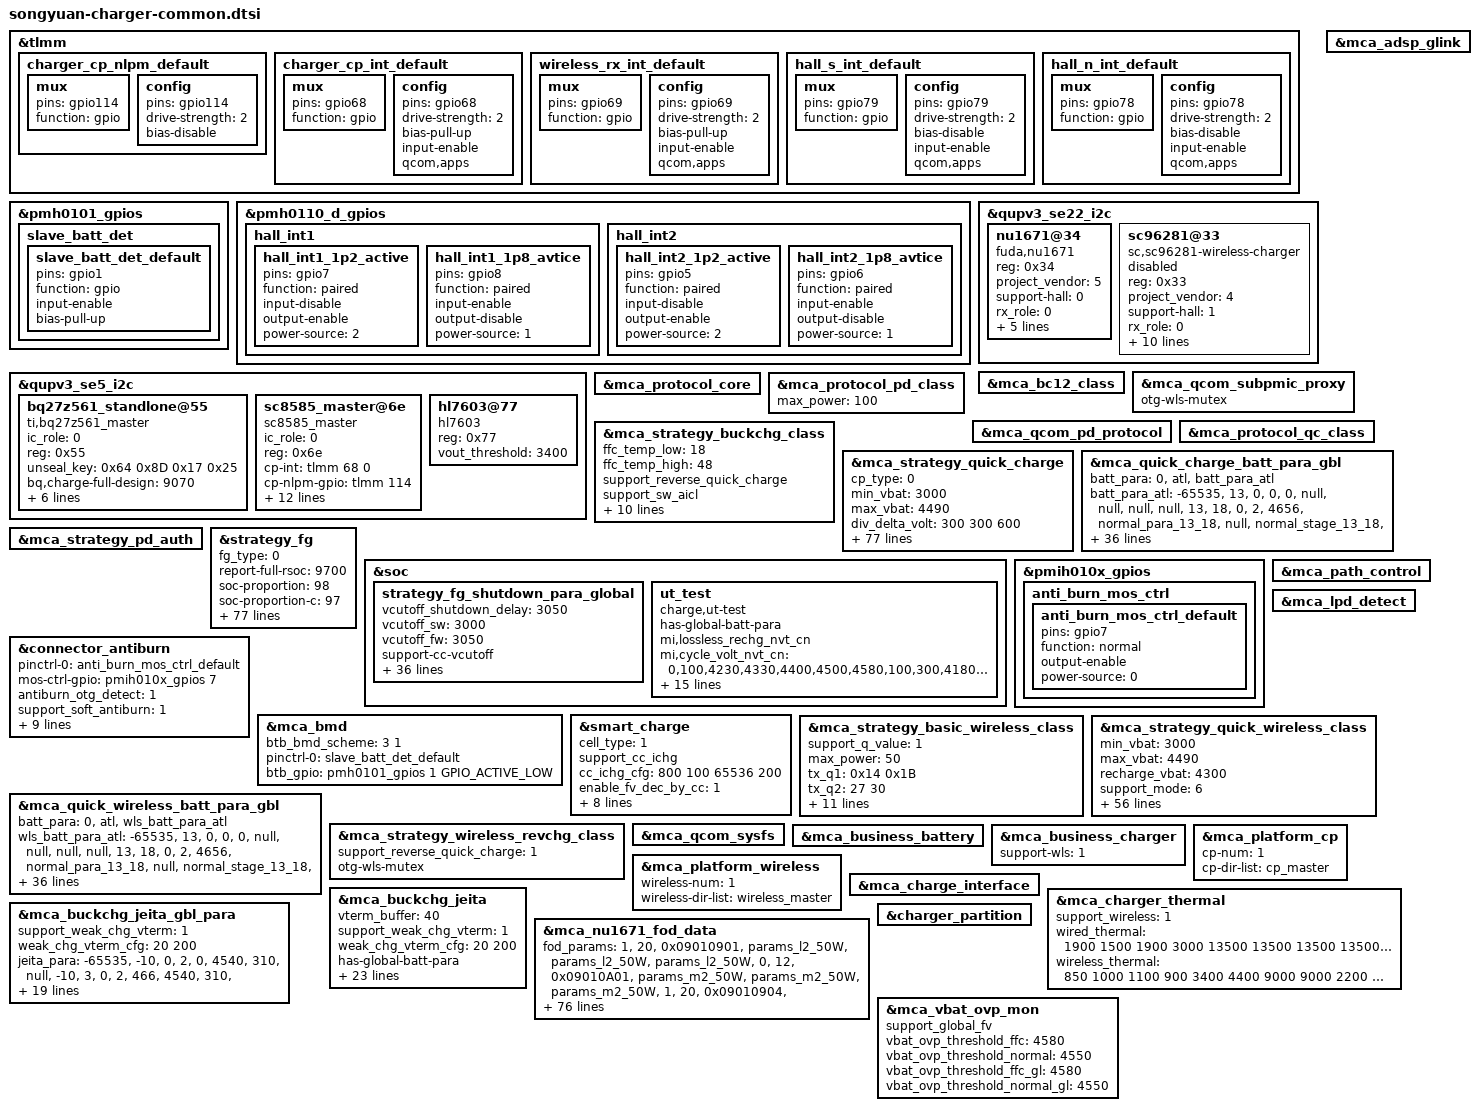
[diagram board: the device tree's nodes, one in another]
#include "mca.dtsi"

&tlmm {
	charger_cp_nlpm_default: charger_cp_nlpm_default {
		mux {
			pins = "gpio114";
			function = "gpio";
		};
		config {
			pins = "gpio114";
			drive-strength = <2>;   /* 2 mA */
			bias-disable;
		};
	};

	charger_cp_int_default: charger_cp_int_default {
		mux {
			pins = "gpio68";
			function = "gpio";
		};
		config {
			pins = "gpio68";
			drive-strength = <2>;   /* 2 mA */
			bias-pull-up;
			input-enable;
			qcom,apps;
		};
	};

	wireless_rx_int_default: wireless_rx_int_default {
		mux {
			pins = "gpio69";
			function = "gpio";
		};

		config {
			pins = "gpio69";
			drive-strength = <2>;
			bias-pull-up;
			input-enable;
			qcom,apps;
		};
	};

	hall_s_int_default: hall_s_int_default {
		mux {
			pins = "gpio79";
			function = "gpio";
		};

		config {
			pins = "gpio79";
			drive-strength = <2>;
			bias-disable;
			input-enable;
			qcom,apps;
		};
	};

	hall_n_int_default: hall_n_int_default {
		mux {
			pins = "gpio78";
			function = "gpio";
		};

		config {
			pins = "gpio78";
			drive-strength = <2>;
			bias-disable;
			input-enable;
			qcom,apps;
		};
	};

};

&pmh0101_gpios {
	slave_batt_det {
		slave_batt_det_default: slave_batt_det_default {
			pins = "gpio1";
			function = "gpio";
			input-enable;
			bias-pull-up;
		};
	};
};

&pmh0110_d_gpios {
	hall_int1 {
		hall_int1_1p2_active: hall_int1_1p2_active {
			pins = "gpio7";
			function = "paired";
			input-disable;
			output-enable;
			power-source = <2>; /* 1.2v */
		};

		hall_int1_1p8_avtice:hall_int1_1p8_avtice {
			pins = "gpio8";
			function = "paired";
			input-enable;
			output-disable;
			power-source = <1>; /* 1.8v */
		};
	};

	hall_int2 {
		hall_int2_1p2_active: hall_int2_1p2_active {
			pins = "gpio5";
			function = "paired";
			input-disable;
			output-enable;
			power-source = <2>; /* 1.2v */
		};

		hall_int2_1p8_avtice:hall_int2_1p8_avtice {
			pins = "gpio6";
			function = "paired";
			input-enable;
			output-disable;
			power-source = <1>; /* 1.8v */
		};
	};
};


&qupv3_se5_i2c {
	status = "ok";
	#address-cells = <1>;
	#size-cells = <0>;
	bq27z561_standlone@55 {
		compatible = "ti,bq27z561_master";
		ic_role = <0>;
		reg = <0x55>;
		unseal_key = /bits/ 8 <0x64 0x8D 0x17 0x25>;
		bq,charge-full-design = <9070>;
		soh_th = <92>;
		cycle_th = <400>;
		cycle_step = <50>;
		resistance-id = <100000>;
		support_batt_manager_4p0;
		support-batt-sn-v2026;
		status = "ok";
	};

	sc8585_master@6e {
		compatible = "sc8585_master";
		status = "ok";
		ic_role = <0>;
		reg = <0x6e>;
		cp-int= <&tlmm 68 0>;
		cp-nlpm-gpio = <&tlmm 114 0x00>;
		pinctrl-names = "default";
		pinctrl-0 = <&charger_cp_nlpm_default>, <&charger_cp_int_default>;
		bat-ovp-threshold = <4700>;
		bat-ovp-alarm-threshold = <4650>;
		bus-ovp-threshold = <21000 12000 6000>;
		usb-ovp-threshold = <21000 14000 7500>;
		bus-ocp-threshold = <5000 5500 5000>;
		wpc-ovp-threshold = <21000>;
		out-ovp-threshold = <5000>;
		pmid2-uvp-threshold = <150 350 100>;
		pmid2-ovp-threshold = <600>;
		ucp-fall-dg = <32000>;
	};

	hl7603@77 {
		compatible = "hl7603";
		reg = <0x77>;
		vout_threshold = <3400>;
	};
};

&qupv3_se22_i2c {
	status = "ok";
	#address-cells = <1>;
	#size-cells = <0>;

	nu1671@34 {
		status = "ok";
		compatible = "fuda,nu1671";
		reg = <0x34>;
		project_vendor = <5>;
		support-hall = <0>;
		rx_role = <0>;
		fw_version_index = <4>;
		pinctrl-names = "default";
		pinctrl-0 = <&wireless_rx_int_default>;
		rx-int = <&tlmm 69 0x00>;
		pwr-det-int = <&tlmm 57 0x00>;
		sleep-rx-gpio = <&tlmm 200 0x00>;

	};

	sc96281@33 {
		status = "disabled";
		compatible = "sc,sc96281-wireless-charger";
		reg = <0x33>;
		project_vendor = <4>;
		support-hall = <1>;
		rx_role = <0>;
		fw_version_index = <1>;
		pinctrl-names = "default";
		pinctrl-0 = <&wireless_rx_int_default>, <&hall_s_int_default>, <&hall_n_int_default>,
					<&hall_int1_1p2_active>, <&hall_int1_1p8_avtice>,
					<&hall_int2_1p2_active>, <&hall_int2_1p8_avtice>;
		rx-int = <&tlmm 69 0x00>;
		pwr-det-int = <&tlmm 57 0x00>;
		sleep-rx-gpio = <&tlmm 200 0x00>;
		hall-s-int = <&tlmm 79 0x00>;
		hall-n-int = <&tlmm 78 0x00>;
	};
};

&mca_adsp_glink {
	status = "ok";
};

&mca_bc12_class {
	status = "ok";
};

&mca_qcom_subpmic_proxy {
	status = "ok";
	otg-wls-mutex;
};

&mca_protocol_core {
	status = "ok";
};

&mca_protocol_pd_class {
	status = "ok";
	max_power = <100>;
};

&mca_qcom_pd_protocol {
	status = "ok";
};

&mca_protocol_qc_class {
	status = "ok";
};


&mca_strategy_buckchg_class {
	status = "ok";
	ffc_temp_low = <18>;
	ffc_temp_high = <48>;
	support_reverse_quick_charge;
	support_sw_aicl;
	support_revchg_screenon;
	support_pps_100w = <3>;
	support_revchg_27w;
	revchg_soc_thr = <60>;
	/* BS(Battery Sense) Vacc enable. Params inherited from mca.dtsi. */
	support_pmic_vacc;
	pmic_iterm_compensation = <70>;
	support_pmic_iterm_dynamics_adjust;
	/* <minimum ITERM, compensation (mA)> */
	pmic_iterm_dynamics_adjust_config =
		<0 30>, /* 0-173mA: compensation 30mA */
		<174 70>;
	ffc_terminated_by_cp = <1>;
};

&mca_strategy_quick_charge {
	status = "ok";
	cp_type = <0>;
	min_vbat = <3000>;
	max_vbat = <4490>;
	div_delta_volt = <300 300 600>;
	div_single_curr = <4500 11000 18400>;
	div_max_curr = <5000 12000 18400>;
	non_mi_pps_max_curr = <4500 11000 18400>;
	support_mode = <6>;
	has-global-batt-para;
	support_cp_vfc = <1>;
	real_curr_max = <17500>;
	support_monitor_current = <17600>;
	curr_monitor_time_s = <120>;
	support_cancel_compensation;
	max_vbat_threshold = <4580>;
	en_buck_parallel_chg = <1>;
	buck_icl_fcc_curr = <1000 3000>;
	buck_en_th = <13000 2500>;
	buck_dis_th = <13000 3850>;
	cp_switch_pmic_th = <1000>;
	drop_fv_value = <10>; /* BS strategy -10mv, drop fv value for BS */

	/* BS(Battery Sense) PMIC&CP dynamic parallel charging (wired) enable.
	 * Params inherited from mca.dtsi.
	 */
	drop_fv_cycle_pdc = <65535>;
	support_pmic_dynamic_chg;

	use-terminate-staged;
	curr_terminate_hys = <300>;
	terminate_staged_para =
		<110 1000>,
		<105 3000>;
	vfc_iout_fsw_map =
		"6000", "720",
		"0", "420";
	batt_depolarize_time_s = <60>;

	/* volt_ratio, cur_gap, vbat_gap, vstep_ratio */
	vstep_para =
		"1", "300", "2000", "0", "2",
		"2", "300", "2000", "0", "4",
		"4", "300", "8000", "0", "25",
		"4", "300", "4000", "20", "17",
		"4", "300", "2000", "10", "5",
		"4", "300", "1200", "10", "5",
		"4", "300", "800", "0", "2",
		"1", "800", "2000", "0", "2",
		"2", "800", "2000", "0", "4",
		"4", "800", "8000", "0", "10",
		"4", "800", "6000", "0", "5",
		"4", "800", "4000", "0", "2";

	batt_para =
		"0", "atl", "batt_para_atl";
	/* temp_low, temp_high, low_hys, high_hys, max_curr, normal_para, ffc_para, normal_stage, ffc_stage */
	batt_para_atl =
		"-65535", "13", "0", "0", "0", "null", "null", "null", "null",
		"13", "18", "0", "2", "5178", "normal_para_atl_13_18", "null", "normal_stage_atl_13_18", "null",
		"18", "23", "0", "1", "12945", "normal_para_atl_18_23", "ffc_para_atl_18_23", "ffc_stage_atl_18_23", "ffc_stage_atl_18_23",
		"23", "35", "0", "0", "18300", "normal_para_atl_23_35", "ffc_para_atl_23_35", "ffc_stage_atl_23_35", "ffc_stage_atl_23_35",
		"35", "40", "1", "0", "18300", "normal_para_atl_35_40", "ffc_para_atl_35_40", "ffc_stage_atl_35_40", "ffc_stage_atl_35_40",
		"40", "48", "1", "0", "18300", "normal_para_atl_40_48", "ffc_para_atl_40_48", "ffc_stage_atl_40_48", "ffc_stage_atl_40_48",
		"48", "65535", "2", "0", "0", "null", "null", "null", "null";

	/* volt, curr_max, curr_min */
	normal_para_atl_13_18 =
		"3900", "5178", "3452",
		"4545", "3452", "432";
	normal_stage_atl_13_18 = <0 1 0 0>;

	normal_para_atl_18_23 =
		"3900", "12945", "9493",
		"4000", "9493", "6904",
		"4150", "6904", "3452",
		"4525", "3452", "432";
	ffc_para_atl_18_23 =
		"3900", "12945", "9493",
		"4000", "9493", "6904",
		"4150", "6904", "3452",
		"4570", "3452", "1014";
	ffc_stage_atl_18_23 = <0 1 0 0 0 0 0 0>;

	normal_para_atl_23_35 =
		"4230", "18300", "12400",
		"4330", "12400", "10356",
		"4400", "10356", "8630",
		"4500", "8630", "6904",
		"4525", "6904", "432";
	ffc_para_atl_23_35 =
		"4230", "18300", "12400",
		"4330", "12400", "10356",
		"4400", "10356", "8630",
		"4500", "8630", "6904",
		"4570", "6904", "1445";
	ffc_stage_atl_23_35 = <0 1 0 0 0 0 0 0 0 0>;

	normal_para_atl_35_40 =
		"4230", "18300", "12400",
		"4330", "12400", "10356",
		"4400", "10356", "8630",
		"4500", "8630", "6904",
		"4505", "6904", "432";
	ffc_para_atl_35_40 =
		"4230", "18300", "12400",
		"4330", "12400", "10356",
		"4400", "10356", "8630",
		"4500", "8630", "6904",
		"4570", "6904", "2107";
	ffc_stage_atl_35_40 = <0 1 0 0 0 0 0 0 0 0>;

	normal_para_atl_40_48 =
		"4230", "18300", "12400",
		"4330", "12400", "10356",
		"4400", "10356", "8630",
		"4495", "8630", "6904",
		"4495", "6904", "432";
	ffc_para_atl_40_48 =
		"4230", "18300", "12400",
		"4330", "12400", "10356",
		"4400", "10356", "8630",
		"4500", "8630", "6904",
		"4570", "6904", "2958";
	ffc_stage_atl_40_48 = <0 1 0 0 0 0 0 0 0 0>;
};

&mca_quick_charge_batt_para_gbl {
	batt_para =
		"0", "atl", "batt_para_atl";
	/* temp_low, temp_high, low_hys, high_hys, max_curr, normal_para, ffc_para, normal_stage, ffc_stage */
	batt_para_atl =
		"-65535", "13", "0", "0", "0", "null", "null", "null", "null",
		"13", "18", "0", "2", "4656", "normal_para_13_18", "null", "normal_stage_13_18", "null",
		"18", "23", "0", "1", "11640", "normal_para_18_23", "null", "normal_stage_13_18", "null",
		"23", "35", "0", "0", "18300", "normal_para_23_35", "ffc_para_23_35", "ffc_stage_23_35", "ffc_stage_23_35",
		"35", "40", "1", "0", "18300", "normal_para_35_40", "ffc_para_35_40", "ffc_stage_35_40", "ffc_stage_35_40",
		"40", "48", "1", "0", "18300", "normal_para_40_48", "ffc_para_40_48", "ffc_stage_40_48", "ffc_stage_40_48",
		"48", "65535", "2", "0", "0", "null", "null", "null", "null";

	/* volt, curr_max, curr_min */
	normal_para_13_18 =
		"4200", "4656", "3104",
		"4545", "3104", "621";
	normal_stage_13_18 = <0 1 0 0>;

	normal_para_18_23 =
		"4250", "11640", "9312",
		"4525", "9312", "621";

	normal_para_23_35 =
		"4110", "18300", "12400",
		"4210", "12400", "11640",
		"4400", "11640", "9312",
		"4500", "9312", "7760",
		"4525", "7760", "621";
	ffc_para_23_35 =
		"4110", "18300", "12400",
		"4210", "12400", "11640",
		"4400", "11640", "9312",
		"4500", "9312", "7760",
		"4575", "7760", "1990";
	ffc_stage_23_35 = <0 1 0 0 0 0 0 0 0 0>;

	normal_para_35_40 =
		"4110", "18300", "12400",
		"4210", "12400", "11640",
		"4400", "11640", "9312",
		"4500", "9312", "7760",
		"4505", "7760", "621";
	ffc_para_35_40 =
		"4110", "18300", "12400",
		"4210", "12400", "11640",
		"4400", "11640", "9312",
		"4500", "9312", "7760",
		"4575", "7760", "3298";
	ffc_stage_35_40 = <0 1 0 0 0 0 0 0 0 0>;

	normal_para_40_48 =
		"4110", "18300", "12400",
		"4210", "12400", "11640",
		"4400", "11640", "9312",
		"4495", "9312", "7760",
		"4495", "7760", "621";
	ffc_para_40_48 =
		"4110", "18300", "12400",
		"4210", "12400", "11640",
		"4400", "11640", "9312",
		"4500", "9312", "7760",
		"4575", "7760", "4982";
	ffc_stage_40_48 = <0 1 0 0 0 0 0 0 0 0>;
};

&mca_strategy_pd_auth {
	status = "ok";
};

&strategy_fg {
	status = "ok";
	fg_type = <0>;
	report-full-rsoc = <9700>;
	soc-proportion = <98>;
	soc-proportion-c = <97>;
	support-pnc;
	support-vpack-low-shutdown;
	has_global_shutdown_para;
	vcutoff_shutdown_delay = <2850>;
	vcutoff_sw = <2800>;
	vcutoff_fw = <2850>;
	vterm_delta = <7>;
	support-normal-early-done-rechg = <1>;
	/* rsoc_min_thr, rsoc_max_thr, rest_time */
	normal-early-done-rechg-cfg = <97 100 300>;
	clear_CC_per_hundred = <0>;

	/* BS(Battery Sense) Vacc + CP dynamic enable. Params inherited from mca.dtsi. */
	support_pmic_vacc;
	support_pmic_cp_dynamic;

	support-cc-vcutoff;
	/* temp_low, temp_high, low_temp_hys, high_temp_hys, vterm_para_name */
	cc_vcutoff_cfg =
		"-65535", "-6", "0", "2", "cc_para0",
		"-6", "0", "2", "2", "cc_para1",
		"0", "10", "2", "2", "cc_para2",
		"10", "60", "2", "0", "cc_para3",
		"60", "65535", "2", "0", "cc_para4";
	/* cycle_count, vterm_fw, vterm_shutdown_delay, vempty */
	cc_para0 =
		"400", "2650", "2600", "2500",
		"800", "2700", "2650", "2600",
		"1200", "2800", "2750", "2700",
		"65535", "2850", "2800", "2750";
	cc_para1 =
		"400", "2650", "2600", "2500",
		"800", "2700", "2650", "2600",
		"1200", "2800", "2750", "2700",
		"65535", "2950", "2900", "2850";
	cc_para2 =
		"400", "2650", "2650", "2600",
		"800", "2850", "2850", "2800",
		"1200", "2950", "2950", "2900",
		"65535", "3050", "3050", "3000";
	cc_para3 =
		"400", "2850", "2850", "2800",
		"800", "3020", "3020", "2970",
		"1200", "3120", "3120", "3070",
		"65535", "3200", "3200", "3150";
	cc_para4 =
		"65535", "3200", "3200", "3150";

	support-dod-vcutoff-v2;
	weight = <20 18 15>;
	/* temp_low, temp_high, low_temp_hys, high_temp_hys, vterm_para_name */
	dod_vcutoff_cfg =
		"-65535", "-6", "0", "2", "dod_para0",
		"-6", "0", "2", "2", "dod_para1",
		"0", "10", "2", "2", "dod_para2",
		"10", "60", "2", "0", "dod_para3",
		"60", "65535", "2", "0", "dod_para4";
	/* dod_count, vterm_fw, vterm_shutdown_delay, vempty */
	dod_para0 =
		"90", "2650", "2600", "2500",
		"169", "2700", "2650", "2600",
		"452", "2800", "2750", "2700",
		"1051", "2850", "2800", "2750",
		"65535", "2950", "2900", "2850";
	dod_para1 =
		"90", "2650", "2600", "2500",
		"169", "2700", "2650", "2600",
		"452", "2800", "2750", "2700",
		"1051", "2950", "2900", "2850",
		"65535", "3050", "3000", "2950";
	dod_para2 =
		"90", "2650", "2650", "2600",
		"169", "2850", "2850", "2800",
		"452", "2950", "2950", "2900",
		"1051", "3050", "3050", "3000",
		"65535", "3110", "3110", "3060";
	dod_para3 =
		"90", "2850", "2850", "2800",
		"169", "3020", "3020", "2970",
		"452", "3120", "3120", "3070",
		"1051", "3200", "3200", "3150",
		"65535", "3250", "3250", "3200";
	dod_para4 =
		"65535", "3250", "3250", "3200";

	adapt_power = <100>;
	model-name = "SONGYUAN_9070mah_100w";
	model-name-global = "SONGYUAN_8050mah_100w";
	support_full_design_gl;
	charge-full-design = <9070>;
	capacity_comp = <0>;
	capacity_comp_gl = <0>;
	support_dynamic_capacity_comp;
	support_dtpt = <1>;
	charge-full-design-gl = <8050>;
	fg_hightemp_vterm = <4200>;
	support-lossless-rechg = <1>;
	lossless-rechg-nor = <0>;
	lossless_rechg_cfg = <18 47 300>;
	support_normal_force_full;
	normal_force_full_hys = <116>;
	support_clear_cycle;
	suppot_RSOC_0_smooth = <1>;
	smooth_temp_unit = <0 150>; //15℃
	smooth_curr_unit = <0 300000 600000 1000000 >;
	smooth_vol_offset = <0x80000000 0 100 200 300 >;
	dischg_smooth_low_temp_unit = <
		10 10 10 10
		20 10 10 10
		40 20 10 10
		80 40 30 20
		150 80 70 50 >;
	dischg_smooth_high_temp_unit = <
		10 10 10 10
		30 20 10 10
		60 40 20 10
		150 70 50 40
		200 150 100 70 >;
	support_extreme_cold = <2>;
	extreme_cold_temp_compemsation =
		"2147483647", "50", "90",
		"2147483647", "600", "80";
};

&soc {
	strategy_fg_shutdown_para_global {
		vcutoff_shutdown_delay = <3050>;
		vcutoff_sw = <3000>;
		vcutoff_fw = <3050>;
		support-cc-vcutoff;
		/* temp_low, temp_high, low_temp_hys, high_temp_hys, vterm_para_name */
		cc_vcutoff_cfg =
			"-65535", "-6", "0", "2", "cc_para0",
			"-6", "0", "2", "2", "cc_para1",
			"0", "10", "2", "2", "cc_para2",
			"10", "60", "2", "0", "cc_para3",
			"60", "65535", "2", "0", "cc_para4";
		/* cycle_count, vterm_fw, vterm_shutdown_delay, vempty */
		cc_para0 =
			"400", "2650", "2600", "2500",
			"800", "2700", "2650", "2600",
			"1200", "2800", "2750", "2700",
			"65535", "2850", "2800","2750";
		cc_para1 =
			"400", "2650", "2600", "2500",
			"800", "2700", "2650", "2600",
			"1200", "2800", "2750", "2700",
			"65535", "2950", "2900","2850";
		cc_para2 =
			"400", "2650", "2650", "2600",
			"800", "2850", "2850", "2800",
			"1200", "2950", "2950", "2900",
			"65535", "3050", "3050","3000";
		cc_para3 =
			"400", "2850", "2850", "2800",
			"800", "3020", "3020", "2970",
			"1200", "3120", "3120", "3070",
			"65535", "3200", "3200","3150";
		cc_para4 =
			"65535", "3200", "3200","3150";
		support-dod-vcutoff-v2;
		weight = <20 18 15>;
		/* temp_low, temp_high, low_temp_hys, high_temp_hys, vterm_para_name */
		dod_vcutoff_cfg =
			"-65535", "-6", "0", "2", "dod_para0",
			"-6", "0", "2", "2", "dod_para1",
			"0", "10", "2", "2", "dod_para2",
			"10", "60", "2", "0", "dod_para3",
			"60", "65535", "2", "0", "dod_para4";
		/* dod_count, vterm_fw, vterm_shutdown_delay, vempty */
		dod_para0 =
			"90", "2650", "2600", "2500",
			"169", "2700", "2650", "2600",
			"452", "2800", "2750", "2700",
			"1051", "2850", "2800", "2750",
			"65535", "2950", "2900", "2850";
		dod_para1 =
			"90", "2650", "2600", "2500",
			"169", "2700", "2650", "2600",
			"452", "2800", "2750", "2700",
			"1051", "2950", "2900", "2850",
			"65535", "3050", "3000", "2950";
		dod_para2 =
			"90", "2650", "2650", "2600",
			"169", "2850", "2850", "2800",
			"452", "2950", "2950", "2900",
			"1051", "3050", "3050", "3000",
			"65535", "3110", "3110", "3060";
		dod_para3 =
			"90", "2850", "2850", "2800",
			"169", "3020", "3020", "2970",
			"452", "3120", "3120", "3070",
			"1051", "3200", "3200", "3150",
			"65535", "3250", "3250", "3200";
		dod_para4 =
			"65535", "3250", "3250", "3200";
	};
};

&pmih010x_gpios {
	anti_burn_mos_ctrl {
		anti_burn_mos_ctrl_default: anti_burn_mos_ctrl_default {
			pins = "gpio7";
			function = "normal";
			output-enable;
			//drive-strength = <2>;
			power-source = <0>;
		};
	};
};

&connector_antiburn {
	status = "ok";
	pinctrl-names = "default";
	pinctrl-0 = <&anti_burn_mos_ctrl_default>;
	mos-ctrl-gpio = <&pmih010x_gpios 7 0>;
	antiburn_otg_detect = <1>;
	support_soft_antiburn = <1>;
	support_hw_antiburn = <1>;
	use_double_ntc = <1>;
	monitor_interval = <1000>;
	thermal-zone-name = "conn_therm";
	thermal-zone-name2 = "conn_therm2";
	max_temp_increase_rate = <4>; /*ntc temperature increase speed per second.*/
	otg_boost_src = <2>; /* BOOST_SRC_EXTERNAL */
	en_src = <0>; /* OTG_EN_BOOST */
	thermal-board-temp-name = "board_sensor_therm";
};

&mca_bmd {
	status = "ok";
	btb_bmd_scheme = <3 1>;
	pinctrl-names = "default";
	pinctrl-0 = <&slave_batt_det_default>;
	btb_gpio = <&pmh0101_gpios 1 GPIO_ACTIVE_LOW>;
};

&smart_charge {
	status = "ok";
	cell_type = <1>;
	support_cc_ichg;
	/* cyclecount delta_ichg*/
	cc_ichg_cfg = <
		800 100
		65536 200>;
	enable_fv_dec_by_cc = <1>;
	smart_bypass_support = <1>;
	smart_bypass_entry_soc = <40>;
	smart_bypass_high_lmt_cfg = <
		(-100) 150 5 5 4500
		151 200 5 5 4500
		201	250	5 5 4500
		251	300	5 5 3500
		301	370	5 5 2500
		371	800	5 5 1000>;
	smart_bypass_med_lmt_cfg = <
		(-100) 150 5 5 18400
		151	200	5 5 18400
		201	250	5 5 18400
		251	300	5 5 8000
		301	370	5 5 5000
		371	800	5 5 2000>;
	smart_bypass_low_lmt_cfg = <
		(-100) 150 5 5 18400
		151	200	5 5 18400
		201	250	5 5 18400
		251	300	5 5 9000
		301	370	5 5 5000
		371	800	5 5 3000>;
};

&mca_path_control {
	status = "ok";
};

&mca_lpd_detect {
	status = "ok";
};

&mca_strategy_basic_wireless_class {
	status = "ok";
	support_q_value = <1>;
	max_power = <50>;
	/* low_inductance_tx_50w, low_inductance_tx_80w */
	tx_q1 = /bits/ 8 <0x14 0x1B>;
	tx_q2 = <27 30>;
	rx_max_iout = <2650 2650>;
	wls_vdd_src = <2>;
	ffc_temp_low = <15>;
	ffc_temp_high = <48>;
	support-hall = <0>;

	support-dynamic-cp = <1>;
	dynamic-cp-uuid = <0x09010A01>;
	dynamic-cp-min-tx-adapter = <14>;
	dynamic-cp-4to2-threshold = <6000>;
	dynamic-cp-2-1-max-fcc = <9200>;

	/* BS(Battery Sense) Vacc for wireless. Params inherited from mca.dtsi. */
	support_pmic_vacc;
};

&mca_strategy_quick_wireless_class {
	status = "ok";
	min_vbat = <3000>;
	max_vbat = <4490>;
	recharge_vbat = <4300>;
	support_mode = <6>;
	div_single_curr = <0 9200 9200>;
	div_max_curr = <0 9200 9200>;
	has-global-batt-para;
	support-hall = <0>;
	exit_fcc = <1000 1500 1500>;

	/* BS(Battery Sense) PMIC&CP dynamic parallel charging (wireless) enable.
	 * Params inherited from mca.dtsi.
	 */
	support_pmic_dynamic_chg;

	batt_para =
		"0", "atl", "wls_batt_para_atl";
	/* temp_low, temp_high, low_temp_hys, high_temp_hys, max_current, volt_para_name stage_para_name*/
	wls_batt_para_atl =
		"-65535", "13", "0", "0", "0", "null", "null", "null", "null",
		"13", "18", "0", "2", "5178", "normal_para_atl_13_18", "null", "normal_stage_atl_13_18", "null",
		"18", "23", "0", "1", "12945", "normal_para_atl_18_23", "ffc_para_atl_18_23", "ffc_stage_atl_18_23", "ffc_stage_atl_18_23",
		"23", "35", "0", "0", "17600", "normal_para_atl_23_35", "ffc_para_atl_23_35", "ffc_stage_atl_23_35", "ffc_stage_atl_23_35",
		"35", "40", "1", "0", "17600", "normal_para_atl_35_40", "ffc_para_atl_35_40", "ffc_stage_atl_35_40", "ffc_stage_atl_35_40",
		"40", "48", "1", "0", "17600", "normal_para_atl_40_48", "ffc_para_atl_40_48", "ffc_stage_atl_40_48", "ffc_stage_atl_40_48",
		"48", "65535", "2", "0", "0", "null", "null", "null", "null";

	/* volt, curr_max, curr_min */
	normal_para_atl_13_18 =
		"3900", "5178", "3452",
		"4550", "3452", "432";
	normal_stage_atl_13_18 = <0 1 0 0>;

	normal_para_atl_18_23 =
		"3900", "12945", "9493",
		"4000", "9493", "6904",
		"4150", "6904", "3452",
		"4530", "3452", "432";
	ffc_para_atl_18_23 =
		"3900", "12945", "9493",
		"4000", "9493", "6904",
		"4150", "6904", "3452",
		"4520", "3452", "1014";
	ffc_stage_atl_18_23 = <0 1 0 1 0 1 0 1 0 1>;

	normal_para_atl_23_35 =
		"4230", "17600", "12400",
		"4330", "12400", "10356",
		"4400", "10356", "8630",
		"4500", "8630", "6904",
		"4530", "6904", "432";
	ffc_para_atl_23_35 =
		"4230", "17600", "12400",
		"4330", "12400", "10356",
		"4400", "10356", "8630",
		"4500", "8630", "6904",
		"4520", "6904", "1445";
	ffc_stage_atl_23_35 = <0 1 0 1 0 1 0 1 0 1>;

	normal_para_atl_35_40 =
		"4230", "17600", "12400",
		"4330", "12400", "10356",
		"4400", "10356", "8630",
		"4500", "8630", "6904",
		"4510", "6904", "432";
	ffc_para_atl_35_40 =
		"4230", "17600", "12400",
		"4330", "12400", "10356",
		"4400", "10356", "6904",
		"4500", "6904", "2107";
	ffc_stage_atl_35_40 = <0 1 0 1 0 1 0 1 0 1>;

	normal_para_atl_40_48 =
		"4230", "17600", "12400",
		"4330", "12400", "10356",
		"4400", "10356", "8630",
		"4500", "8630", "6904",
		"4500", "6904", "432";
	ffc_para_atl_40_48 =
		"4230", "17600", "12400",
		"4330", "12400", "10356",
		"4400", "10356", "6904",
		"4500", "6904", "2958";
	ffc_stage_atl_40_48 = <0 1 0 1 0 1 0 1 0 1>;

	vstep_para =
		"1", "2000", "2",
		"2", "4000", "25",
		"2", "3000", "25",
		"2", "2000", "4",
		"4", "4000", "25",
		"4", "3000", "25",
		"4", "2000", "6",
		"4", "1000", "3",
		"4", "500", "2",
		"4", "200", "1";
};

&mca_quick_wireless_batt_para_gbl {
	batt_para =
		"0", "atl", "wls_batt_para_atl";
	/* temp_low, temp_high, low_temp_hys, high_temp_hys, max_current, volt_para_name stage_para_name*/
	wls_batt_para_atl =
		"-65535", "13", "0", "0", "0", "null", "null", "null", "null",
		"13", "18", "0", "2", "4656", "normal_para_13_18", "null", "normal_stage_13_18", "null",
		"18", "23", "0", "1", "11640", "normal_para_18_23", "null", "normal_stage_13_18", "null",
		"23", "35", "0", "0", "17600", "normal_para_23_35", "ffc_para_23_35", "ffc_stage_23_35", "ffc_stage_23_35",
		"35", "40", "1", "0", "17600", "normal_para_35_40", "ffc_para_35_40", "ffc_stage_35_40", "ffc_stage_35_40",
		"40", "48", "1", "0", "17600", "normal_para_40_48", "ffc_para_40_48", "ffc_stage_40_48", "ffc_stage_40_48",
		"48", "65535", "0", "0", "0", "null", "null", "null", "null";

	/* volt, curr_max, curr_min */
	normal_para_13_18 =
		"4200", "4656", "3104",
		"4550", "3104", "621";
	normal_stage_13_18 = <0 1 0 0>;

	normal_para_18_23 =
		"4250", "11640", "9312",
		"4530", "9312", "621";

	normal_para_23_35 =
		"4110", "17600", "12400",
		"4210", "12400", "11640",
		"4400", "11640", "9312",
		"4500", "9312", "7760",
		"4530", "7760", "621";
	ffc_para_23_35 =
		"4110", "17600", "12400",
		"4210", "12400", "11640",
		"4400", "11640", "9312",
		"4500", "9312", "7760",
		"4580", "7760", "1990";
	ffc_stage_23_35 = <0 1 0 0 0 0 0 0 0 0>;

	normal_para_35_40 =
		"4110", "17600", "12400",
		"4210", "12400", "11640",
		"4400", "11640", "9312",
		"4500", "9312", "7760",
		"4510", "7760", "621";
	ffc_para_35_40 =
		"4110", "17600", "12400",
		"4210", "12400", "11640",
		"4400", "11640", "9312",
		"4500", "9312", "7760",
		"4580", "7760", "3298";
	ffc_stage_35_40 = <0 1 0 0 0 0 0 0 0 0>;

	normal_para_40_48 =
		"4110", "17600", "12400",
		"4210", "12400", "11640",
		"4400", "11640", "9312",
		"4500", "9312", "7760",
		"4500", "7760", "621";
	ffc_para_40_48 =
		"4110", "17600", "12400",
		"4210", "12400", "11640",
		"4400", "11640", "9312",
		"4500", "9312", "7760",
		"4580", "7760", "4982";
	ffc_stage_40_48 = <0 1 0 0 0 0 0 0 0 0>;
};

&mca_strategy_wireless_revchg_class {
	status = "ok";
	support_reverse_quick_charge = <1>;
	otg-wls-mutex;
};

&mca_qcom_sysfs {
	status = "ok";
};

&mca_business_battery {
	status = "ok";
};

&mca_business_charger {
	support-wls = <1>;
	status = "ok";
};

&mca_platform_cp {
	status = "ok";
	cp-num = <1>;
	cp-dir-list = "cp_master";
};

&mca_platform_wireless {
	status = "ok";
	wireless-num = <1>;
	wireless-dir-list = "wireless_master";
};

&mca_charge_interface {
	status = "ok";
};

&mca_charger_thermal {
	status = "ok";
	support_wireless = <1>;
	/* 5v_in 9v_in 5v_ichg 9v_ichg div1_single div1_multi div2_single div2_multi div4_single div4_multi*/
	wired_thermal = <
		1900 1500 1900 3000 13500 13500 13500 13500 13500 13500 /* level 1 */
		1900 1500 1900 3000 11000 11000 11000 11000 11000 11000 /* level 2 */
		1900 1500 1900 3000 9000  9000  9000  9000  9000  9000  /* level 3 */
		1900 1450 1900 3000 8000  8000  8000  8000  8000  8000  /* level 4 */
		1900 1400 1900 3000 7000  7000  7000  7000  7000  7000  /* level 5 */
		1900 1350 1900 2800 6000  6000  6000  6000  6000  6000  /* level 6 */
		1900 1300 1900 2600 5000  5000  5000  5000  5000  5000  /* level 7 */
		1900 1150 1900 2310 4000  4000  4000  4000  4000  4000  /* level 8 */
		1700 1100 1700 2200 3500  3500  3500  3500  3500  3500  /* level 9 */
		1600 1000 1600 2000 3000  3000  3000  3000  3000  3000  /* level 10 */
		1400 900  1500 2000 2500  2500  2500  2500  2500  2500  /* level 11 */
		1200 850  1500 2000 2000  2000  2000  2000  2000  2000  /* level 12 */
		1100 750  1500 1500 1500  1500  1500  1500  1500  1500  /* level 13 */
		1100 650  1000 1000 1000  1000  1000  1000  1000  1000  /* level 14 */
		1100 600  500  500  500   500   500   500   500   500   /* level 15 */
	>;
	/* bpp_in bpp_qc2 bpp_qc3 epp_in cp_20w cp_30w cp_50w cp_80w voice_box magnet_30w xiaomi_car */
	wireless_thermal = <
		850 1000 1100 900 3400 4400 9000 9000 2200 4400 9000  /* level 1 */
		850 1000 1100 750 3200 4200 8000 8000 2200 4200 8000  /* level 2 */
		850 1000 1100 650 2200 3400 7000 7000 1000 3400 7000  /* level 3 */
		700 1000 1100 650 1800 2800 6000 6000 1000 2800 6000  /* level 4 */
		700 1000  700 650 1500 2600 5000 5000  800 2600 5000  /* level 5 */
		500 1000  700 650 1300 2200 4000 4000  800 2200 4000  /* level 6 */
		500  700  600 400 1100 2200 3500 3500  700 2200 3500  /* level 7 */
		500  700  600 400 1000 1800 3000 3000  700 1800 3000  /* level 8 */
		500  500  500 300  800 1100 2500 2500  600 1100 2500  /* level 9 */
		400  500  500 300  700 1000 2000 2000  600 1000 2000  /* level 10 */
		400  500  500 250  600  800 1500 1500  500  800 1500  /* level 11 */
		400  500  500 250  500  700 1000 1000  500  700 1000  /* level 12 */
		300  500  500 250  500  600  800  800  400  600  800   /* level 13 */
		300  400  400 200  400  500  500  500  400  500  500   /* level 14 */
		300  300  300 150  300  400  400  400  300  400  400   /* level 15 */
	>;
};

&mca_buckchg_jeita {
	status = "ok";
	vterm_buffer = <40>;
	support_weak_chg_vterm = <1>;
	weak_chg_vterm_cfg = <20 200>;
	has-global-batt-para;
	/* temp_low, temp_high, low_temp_hys, high_temp_hys, max_current, vterm, iterm volt_para_name */
	jeita_para =
		"-65535", "-10", "0", "2", "0", "4540", "86", "null",
		"-10", "-2", "0", "2", "345", "4540", "86", "para_n10_n2",
		"-2", "3", "0", "2", "690", "4540", "173", "para_n2_3",
		"3", "8", "0", "2", "1036", "4550", "432", "para_3_8",
		"8", "13", "0", "2", "2589", "4550", "432", "para_8_13",
		"13", "18", "0", "2", "5178", "4550", "432", "para_13_18",
		"18", "23", "0", "1", "12945", "4530", "432", "null",
		"23", "35", "0", "0", "17600", "4530", "432", "null",
		"35", "40", "1", "0", "17600", "4510", "432", "null",
		"40", "48", "1", "0", "17600", "4500", "432", "null",
		"48", "55", "2", "0", "4315", "4080", "432", "null",
		"55", "65535", "2", "2", "0", "4080", "432", "null";
	para_n10_n2 =
		"4000", "345",
		"4540", "173";
	para_n2_3 =
		"4000", "690",
		"4540", "432";
	para_3_8 =
		"4000", "1036",
		"4200", "863",
		"4550", "690";
	para_8_13 =
		"3900", "2589",
		"4550", "1726";
	para_13_18 =
		"3900", "5178",
		"4550", "3452";
	jeita_para_ffc =
		"18", "23", "0", "1", "12945", "4580", "1014", "null",
		"23", "35", "0", "0", "17600", "4580", "1445", "null",
		"35", "40", "1", "0", "17600", "4580", "2107", "null",
		"40", "48", "1", "0", "17600", "4580", "2958", "null",
		"48", "55", "2", "0", "17600", "4080", "432", "null",
		"55", "65535", "2", "2", "0", "4080", "432", "null";
};

&mca_buckchg_jeita_gbl_para {
	support_weak_chg_vterm = <1>;
	weak_chg_vterm_cfg = <20 200>;
	/* temp_low, temp_high, low_temp_hys, high_temp_hys, max_current, vterm, iterm volt_para_name */
	jeita_para =
		"-65535", "-10", "0", "2", "0", "4540", "310", "null",
		"-10", "3", "0", "2", "466", "4540", "310", "para_n10_3",
		"3", "8", "0", "2", "1164", "4550", "621", "para_3_8",
		"8", "13", "0", "2", "2328", "4550", "621", "para_8_13",
		"13", "18", "0", "2", "4656", "4550", "621", "para_13_18",
		"18", "23", "0", "1", "11640", "4530", "621", "para_18_23",
		"23", "35", "0", "0", "17600", "4530", "621", "null",
		"35", "40", "1", "0", "17600", "4510", "621", "null",
		"40", "48", "1", "0", "17600", "4500", "621", "null",
		"48", "55", "2", "0", "3880", "4080", "621", "null",
		"55", "65535", "2", "2", "0", "4080", "621", "null";
	para_n10_3 =
		"4540", "466";
	para_3_8 =
		"4200", "1164",
		"4550", "776";
	para_8_13 =
		"4200", "2328",
		"4550", "1552";
	para_13_18 =
		"4200", "4656",
		"4550", "3104";
	para_18_23 =
		"4250", "11640",
		"4530", "9312";
	jeita_para_ffc =
		"23", "35", "0", "0", "17600", "4580", "621", "null",
		"35", "40", "1", "0", "17600", "4580", "621", "null",
		"40", "48", "1", "0", "17600", "4580", "621", "null",
		"48", "55", "2", "0", "3880", "4080", "621", "null",
		"55", "65535", "2", "2", "0", "4080", "621", "null";
};

&mca_nu1671_fod_data {

	fod_params =
		"1", "20", "0x09010901", "params_l2_50W", "params_l2_50W", "params_l2_50W",
		"0", "12", "0x09010A01", "params_m2_50W", "params_m2_50W", "params_m2_50W",
		"1", "20", "0x09010904", "params_k1_80W", "params_k1_80W", "params_k1_80W",
		"1", "20", "0x0901090C", "params_k8_100W", "params_k8_100W", "params_k8_100W",
		"0", "12", "0x09010305", "params_n1_80W", "params_n1_80W", "params_n1_80W",
		"1", "20", "0x09010A07", "params_double_coil_30W", "params_double_coil_30W", "params_double_coil_30W",
		"2", "7",  "0x01020D03", "params_trx_rev_22P5W", "params_trx_rev_22P5W", "params_trx_rev_22P5W",
		"1", "20", "0x0901010B", "params_j1s_55W", "params_j1s_55W", "params_j1s_55W",
		"1", "20", "0x09080108", "params_zimi_20W", "params_zimi_20W", "params_zimi_20W",
		"1", "20", "0x07030801", "params_power_bank_30W", "params_power_bank_30W", "params_power_bank_30W",
		"1", "20", "0x09080607", "params_bluetooth_30W", "params_bluetooth_30W", "params_bluetooth_30W",
		"1", "20", "0x0C090908", "params_multcoil_20W", "params_multcoil_20W", "params_multcoil_20W",
		"1", "20", "0x09010407", "params_white_stand_30W", "params_white_stand_30W", "params_white_stand_30W",
		"1", "20", "0x06020801", "params_zimi_car_20W_2_1", "params_zimi_car_20W_2_1", "params_zimi_car_20W_2_1";

	/* type, length, uuid, params_no_mag, params_mag_thin, params_mag_thick */
	fod_params_default =
		"0", "12", "0x00000000", "params_default", "params_default", "params_default";
	params_default = /bits/ 8 <
		10 40
		10 40
		10 40
		8  47
		7  46
		7  53
		7  47
		7  49
		7  48
		7  46
		7  46
		7  46
	>;
	/* type, length, uuid, params_no_mag, params_mag_thin, params_mag_thick */
	fod_params_bpp_plus =
		"2", "7",  "0x00000000", "params_bpp_plus", "params_bpp_plus", "params_bpp_plus";
	params_bpp_plus = /bits/ 8 <
		10 50
		10 50
		8  50
		8  50
		8  50
		8  50
		8  50
	>;
	fod_params_2_1 =
		"1", "20", "0x09010A01", "params_m2_50W_2_1", "params_m2_50W_2_1", "params_m2_50W_2_1",
		"1", "20", "0x09010305", "params_n1_80W_2_1", "params_n1_80W_2_1", "params_n1_80W_2_1";
	/* gain, offset */
	params_m2_50W_2_1 = /bits/ 8 <
		0 35
		0 32
		0 25
		0 26
		0 22
		0 25
		0 23
		1 18
		1 21
		1 19
		1 18
		1 18
		2 13
		2 17
		2 18
		2 22
		2 33
		2 36
		2 36
		2 38
	>;
	params_n1_80W_2_1 = /bits/ 8 <
		0 13
		0 13
		0 11
		0 11
		0 10
		0 17
		0 14
		1 12
		1 16
		1 18
		1 20
		1 20
		2 16
		2 16
		2 20
		2 22
		2 25
		2 31
		2 31
		2 33
	>;

	params_l2_50W = /bits/ 8 <
		0 32
		0 29
		0 27
		0 26
		0 27
		0 26
		0 29
		1 26
		1 28
		1 33
		1 36
		1 40
		2 35
		2 31
		2 38
		2 31
		2 37
		2 37
		2 45
		2 38
	>;

	params_m2_50W = /bits/ 8 <
		10 40
		10 30
		10 30
		8  40
		7  33
		7  43
		7  42
		7  40
		7  46
		7  46
		7  46
		7  46
	>;
	params_j1s_55W = /bits/ 8 <
		0 32
		0 29
		0 27
		0 26
		0 27
		0 26
		0 29
		1 26
		1 28
		1 33
		1 36
		1 40
		2 35
		2 31
		2 38
		2 31
		2 37
		2 37
		2 45
		2 38
	>;
	params_zimi_20W = /bits/ 8 <
		0 32
		0 29
		0 27
		0 29
		0 27
		0 30
		0 34
		1 35
		1 25
		1 33
		1 36
		1 40
		2 35
		2 31
		2 38
		2 31
		2 37
		2 37
		2 45
		2 38
	>;
	params_power_bank_30W = /bits/ 8 <
		0 32
		0 29
		0 27
		0 26
		0 27
		0 26
		0 29
		1 26
		1 28
		1 33
		1 36
		1 40
		2 35
		2 31
		2 38
		2 31
		2 37
		2 37
		2 45
		2 38
	>;
	params_bluetooth_30W = /bits/ 8 <
		0 32
		0 29
		0 27
		0 26
		0 27
		0 26
		0 29
		1 26
		1 28
		1 33
		1 36
		1 40
		2 35
		2 31
		2 38
		2 31
		2 37
		2 37
		2 45
		2 38
	>;
	params_multcoil_20W = /bits/ 8 <
		0 32
		0 29
		0 27
		0 26
		0 27
		0 26
		0 29
		1 26
		1 28
		1 33
		1 36
		1 40
		2 35
		2 31
		2 38
		2 31
		2 37
		2 37
		2 45
		2 38
	>;
	params_white_stand_30W = /bits/ 8 <
		0 32
		0 29
		0 27
		0 29
		0 29
		0 28
		0 29
		1 28
		1 32
		1 32
		1 37
		1 40
		2 42
		2 42
		2 42
		2 42
		2 42
		2 42
		2 42
		2 42
	>;

	params_k8_100W = /bits/ 8 <
		0 32
		0 31
		0 26
		0 26
		0 24
		0 28
		0 30
		1 29
		1 33
		1 37
		1 40
		1 41
		2 35
		2 39
		2 40
		2 43
		2 49
		2 55
		2 52
		2 91
	>;
	params_k1_80W = /bits/ 8 <
		0 32
		0 31
		0 26
		0 26
		0 24
		0 28
		0 30
		1 29
		1 33
		1 37
		1 40
		1 41
		2 35
		2 39
		2 40
		2 43
		2 49
		2 55
		2 56
		2 91
	>;
	params_k1_80W_mag = /bits/ 8 <
		0 77
		0 55
		0 53
		0 56
		0 55
		0 55
		0 60
		1 60
		1 63
		1 67
		1 77
		1 80
		2 80
		2 84
		2 90
		2 87
		2 92
		2 104
		2 110
		2 114
	>;

	params_n1_80W = /bits/ 8 <
		10 10
		10 0
		8  251
		0  0
		0  2
		0  5
		0  5
		0  8
		0  9
		0  11
		0  11
		0  11
	>;
	params_double_coil_30W = /bits/ 8 <
		0 25
		0 16
		0 19
		0 12
		0 16
		0 15
		0 23
		1 25
		1 27
		1 33
		1 40
		1 48
		2 40
		2 62
		2 64
		2 64
		2 64
		2 67
		2 67
		2 69
	>;
	params_zimi_car_20W_2_1 = /bits/ 8 <
		0 72
		0 58
		0 25
		0 27
		0 27
		0 29
		0 29
		1 30
		1 39
		1 39
		1 40
		1 62
		2 59
		2 64
		2 72
		2 75
		2 85
		2 95
		2 99
		2 101
	>;
	params_trx_rev_22P5W = /bits/ 8 <
		10 1
		8  1
		7  0
		5  0
		4  255
		4  255
		4  1
	>;
};

&charger_partition {
	status = "ok";
};

&mca_vbat_ovp_mon {
	status = "ok";
	support_global_fv;
	vbat_ovp_threshold_ffc = <4580>;
	vbat_ovp_threshold_normal = <4550>;
	vbat_ovp_threshold_ffc_gl = <4580>;
	vbat_ovp_threshold_normal_gl = <4550>;
};

&soc {
	ut_test {
		compatible = "charge,ut-test";
		status = "ok";
		has-global-batt-para;

		mi,lossless_rechg_nvt_cn;
		mi,cycle_volt_nvt_cn = "0,100,4230,4330,4400,4500,4580,100,300,4180,4300,4400,4480,4560,300,800,4180,4300,4400,4460,4550,800,10000,4180,4300,4400,4440,4530";
		mi,cycle_step_curr_nvt_cn = "0,100,17600,12400,10356,8630,6904,100,300,17600,11780,9838,8199,6559,300,800,17600,11160,9320,7767,6214,800,10000,14080,9920,8285,6904,5523";
		mi,temp_term_curr_nvt_cn = "23,35,1445,35,40,2107,40,48,2958";
		mi,thermal_nvt_cn = "17600,13500,11000,9000,8000,7000,6000,5000,4000,3500,3000,2500,2000,1500,1000,500";

		mi,lossless_rechg_nvt_global;
		mi,cycle_volt_nvt_global = "0,100,4110,4210,4400,4500,4580,100,300,4060,4180,4400,4480,4560,300,800,4060,4180,4400,4460,4550,800,10000,4060,4180,4400,4440,4530";
		mi,cycle_step_curr_nvt_global = "0,100,17600,12400,11640,9312,7760,100,300,17600,11780,11058,8846,7372,300,800,17600,11160,10476,8381,6984,800,10000,14080,9920,9312,7450,6208";
		mi,temp_term_curr_nvt_global = "23,35,1990,35,40,3298,40,48,4982";
		mi,thermal_nvt_global = "17600,13500,11000,9000,8000,7000,6000,5000,4000,3500,3000,2500,2000,1500,1000,500";
	};
};
